# M2Sxxx register map
Vendor: Microsemi; Series: SmartFusion2; File version: 2.0.32
CPU: CM3 r2p1, little endian, MPU, no FPU, 4 interrupt priority bits
Registers are 32-bit, read-write, no defined reset value unless marked. A register's access mark holds for its fields unless they carry their own. Offsets are from the block's base; [hi:lo] are bit positions.

## FDDR — No description provided for this peripheral
Base 0x40021000
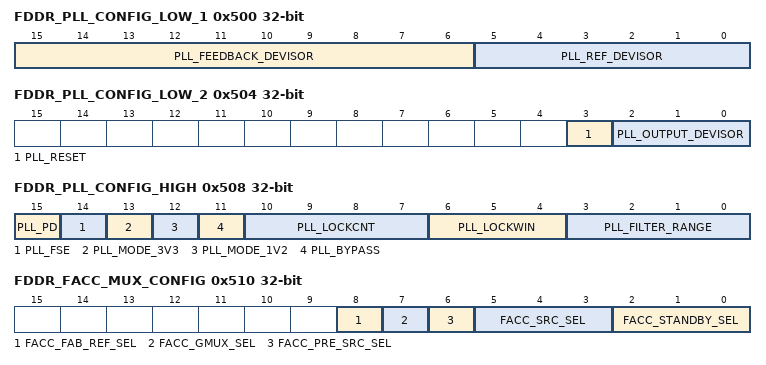
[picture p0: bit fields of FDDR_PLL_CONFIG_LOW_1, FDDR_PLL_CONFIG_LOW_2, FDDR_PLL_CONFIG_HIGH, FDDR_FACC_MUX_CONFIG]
0x500 FDDR_PLL_CONFIG_LOW_1 — No description provided for this register
  [15:6] PLL_FEEDBACK_DEVISOR — No description provided for this field
  [5:0] PLL_REF_DEVISOR — No description provided for this field
0x504 FDDR_PLL_CONFIG_LOW_2 — No description provided for this register
  [3] PLL_RESET — No description provided for this field
  [2:0] PLL_OUTPUT_DEVISOR — No description provided for this field
0x508 FDDR_PLL_CONFIG_HIGH — No description provided for this register
  [15] PLL_PD — No description provided for this field
  [14] PLL_FSE — No description provided for this field
  [13] PLL_MODE_3V3 — No description provided for this field
  [12] PLL_MODE_1V2 — No description provided for this field
  [11] PLL_BYPASS — No description provided for this field
  [10:7] PLL_LOCKCNT — No description provided for this field
  [6:4] PLL_LOCKWIN — No description provided for this field
  [3:0] PLL_FILTER_RANGE — No description provided for this field
0x50C FDDR_FAC_CLKEN — No description provided for this register
  [0] DDR_CLK_EN — No description provided for this field
0x510 FDDR_FACC_MUX_CONFIG — No description provided for this register
  [8] FACC_FAB_REF_SEL — No description provided for this field
  [7] FACC_GMUX_SEL — No description provided for this field
  [6] FACC_PRE_SRC_SEL — No description provided for this field
  [5:3] FACC_SRC_SEL — No description provided for this field
  [2:0] FACC_STANDBY_SEL — No description provided for this field
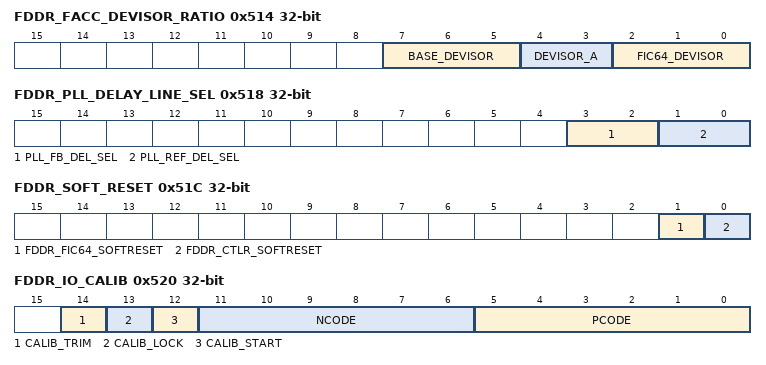
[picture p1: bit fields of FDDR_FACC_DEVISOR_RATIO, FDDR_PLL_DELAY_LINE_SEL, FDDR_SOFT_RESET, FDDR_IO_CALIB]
0x514 FDDR_FACC_DEVISOR_RATIO — No description provided for this register
  [7:5] BASE_DEVISOR — No description provided for this field
  [4:3] DEVISOR_A — No description provided for this field
  [2:0] FIC64_DEVISOR — No description provided for this field
0x518 FDDR_PLL_DELAY_LINE_SEL — No description provided for this register
  [3:2] PLL_FB_DEL_SEL — No description provided for this field
  [1:0] PLL_REF_DEL_SEL — No description provided for this field
0x51C FDDR_SOFT_RESET — No description provided for this register
  [1] FDDR_FIC64_SOFTRESET — No description provided for this field
  [0] FDDR_CTLR_SOFTRESET — No description provided for this field
0x520 FDDR_IO_CALIB — No description provided for this register
  [14] CALIB_TRIM — No description provided for this field
  [13] CALIB_LOCK — No description provided for this field
  [12] CALIB_START — No description provided for this field
  [11:6] NCODE — No description provided for this field
  [5:0] PCODE — No description provided for this field
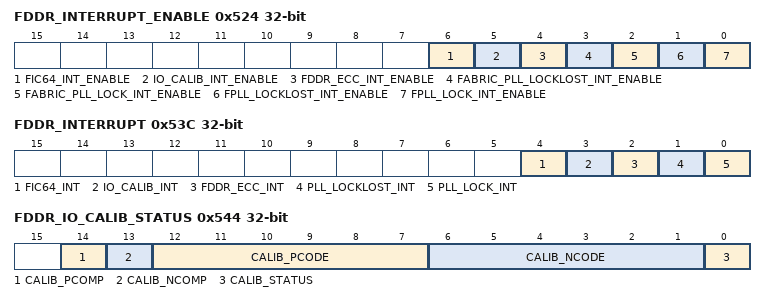
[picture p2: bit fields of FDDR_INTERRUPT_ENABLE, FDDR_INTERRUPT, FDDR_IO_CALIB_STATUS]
0x524 FDDR_INTERRUPT_ENABLE — No description provided for this register
  [6] FIC64_INT_ENABLE — No description provided for this field
  [5] IO_CALIB_INT_ENABLE — No description provided for this field
  [4] FDDR_ECC_INT_ENABLE — No description provided for this field
  [3] FABRIC_PLL_LOCKLOST_INT_ENABLE — No description provided for this field
  [2] FABRIC_PLL_LOCK_INT_ENABLE — No description provided for this field
  [1] FPLL_LOCKLOST_INT_ENABLE — No description provided for this field
  [0] FPLL_LOCK_INT_ENABLE — No description provided for this field
0x528 FDDR_AXI_AHB_MODE_SEL — No description provided for this register
  [0] F_AXI_AHB_MODE — No description provided for this field
0x52C FDDR_PHY_SELF_REF_EN — No description provided for this register
  [0] PHY_SELF_REF_EN — No description provided for this field
0x530 FDDR_FAB_PLL_CLK_STATUS — No description provided for this register
  [0] FAB_PLL_LOCK — No description provided for this field
0x534 FDDR_FPLL_CLK_STATUS — No description provided for this register
  [0] FPLL_CLK_STATUS — No description provided for this field
0x538 FDDR_CLK_CALIB_STATUS — No description provided for this register
  [0] FABCALIBFAIL — No description provided for this field
0x53C FDDR_INTERRUPT — No description provided for this register
  [4] FIC64_INT — No description provided for this field
  [3] IO_CALIB_INT — No description provided for this field
  [2] FDDR_ECC_INT — No description provided for this field
  [1] PLL_LOCKLOST_INT — No description provided for this field
  [0] PLL_LOCK_INT — No description provided for this field
0x540 FDDR_CLK_CALIB_CONFIG — No description provided for this register
  [0] FABCALIBSTART — No description provided for this field
0x544 FDDR_IO_CALIB_STATUS — No description provided for this register
  [14] CALIB_PCOMP — No description provided for this field
  [13] CALIB_NCOMP — No description provided for this field
  [12:7] CALIB_PCODE — No description provided for this field
  [6:1] CALIB_NCODE — No description provided for this field
  [0] CALIB_STATUS — No description provided for this field
0x548 FDDR_FATC_RESET — No description provided for this register
  [0] FATC_RESET — No description provided for this field
